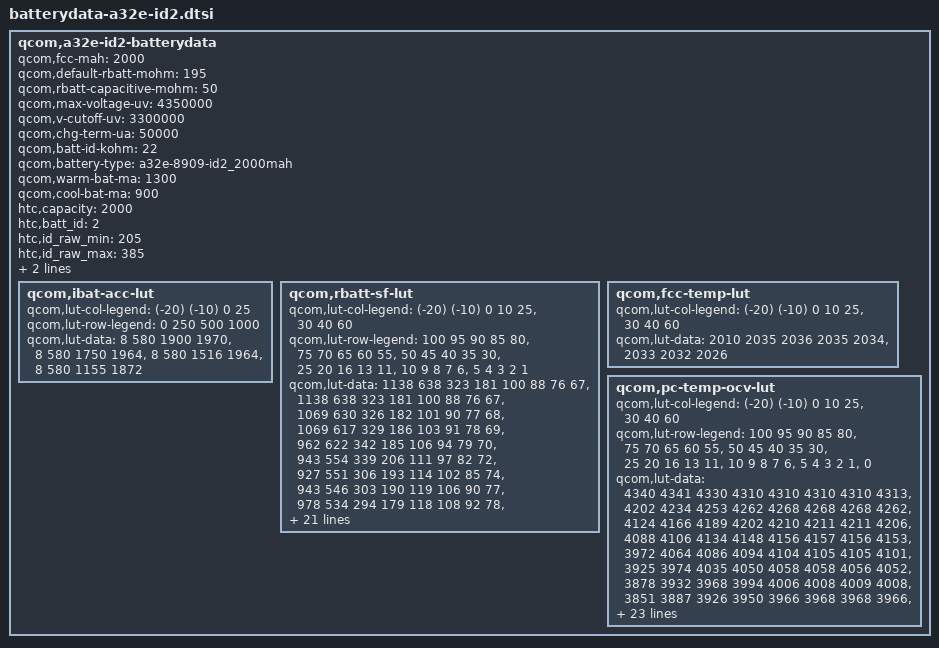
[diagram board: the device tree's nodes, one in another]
/* Copyright (c) 2013, The Linux Foundation. All rights reserved.
 *
 * This program is free software; you can redistribute it and/or modify
 * it under the terms of the GNU General Public License version 2 and
 * only version 2 as published by the Free Software Foundation.
 *
 * This program is distributed in the hope that it will be useful,
 * but WITHOUT ANY WARRANTY; without even the implied warranty of
 * MERCHANTABILITY or FITNESS FOR A PARTICULAR PURPOSE.  See the
 * GNU General Public License for more details.
 */

qcom,a32e-id2-batterydata {
	qcom,fcc-mah = <2000>;
	qcom,default-rbatt-mohm = <195>;
	qcom,rbatt-capacitive-mohm = <50>;
	qcom,max-voltage-uv = <4350000>;
	qcom,v-cutoff-uv = <3300000>;
	qcom,chg-term-ua = <50000>;
	qcom,batt-id-kohm = <22>;
	qcom,battery-type = "a32e-8909-id2_2000mah";
	qcom,warm-bat-ma = <1300>;
	qcom,cool-bat-ma = <900>;
	htc,capacity = <2000>;
	htc,batt_id = <2>;
	htc,id_raw_min = <205>;
	htc,id_raw_max = <385>;
	htc,type = <1>;
	htc,model_name = "B0PKX100";

	qcom,ibat-acc-lut {
		qcom,lut-col-legend = <(-20) (-10) 0 25>;
		qcom,lut-row-legend = <0 250 500 1000>;
		qcom,lut-data = <8 580 1900 1970>,
				<8 580 1750 1964>,
				<8 580 1516 1964>,
				<8 580 1155 1872>;
	};

	qcom,rbatt-sf-lut {
		qcom,lut-col-legend = <(-20) (-10) 0 10 25>,
				<30 40 60>;
		qcom,lut-row-legend = <100 95 90 85 80>,
				<75 70 65 60 55>,
				<50 45 40 35 30>,
				<25 20 16 13 11>,
				<10 9 8 7 6>,
				<5 4 3 2 1>;
		qcom,lut-data = <1138 638 323 181 100 88 76 67>,
				<1138 638 323 181 100 88 76 67>,
				<1069 630 326 182 101 90 77 68>,
				<1069 617 329 186 103 91 78 69>,
				<962 622 342 185 106 94 79 70>,
				<943 554 339 206 111 97 82 72>,
				<927 551 306 193 114 102 85 74>,
				<943 546 303 190 119 106 90 77>,
				<978 534 294 179 118 108 92 78>,
				<1024 550 287 168 102 91 79 70>,
				<1081 582 283 163 98 88 76 68>,
				<1139 636 303 161 99 90 78 70>,
				<1200 684 338 163 101 91 82 73>,
				<1270 738 383 181 101 92 84 75>,
				<1449 797 443 212 104 91 80 73>,
				<1731 867 503 254 111 94 78 69>,
				<2138 934 560 294 122 99 80 70>,
				<2604 1000 613 324 132 107 82 69>,
				<3047 1046 655 347 137 111 83 69>,
				<3273 1035 660 355 136 110 85 71>,
				<3386 1059 681 369 143 115 88 72>,
				<3680 1087 705 385 150 119 90 74>,
				<4026 1117 730 405 159 126 93 76>,
				<4434 1171 757 426 168 132 96 77>,
				<4942 1268 783 444 174 135 96 76>,
				<5607 1411 806 456 176 135 94 74>,
				<6570 1606 834 475 185 141 97 75>,
				<8048 1884 875 506 198 149 102 77>,
				<11056 2318 977 547 215 161 107 81>,
				<22112 3161 1275 604 241 181 120 97>;
	};

	qcom,fcc-temp-lut {
		qcom,lut-col-legend = <(-20) (-10) 0 10 25>,
				<30 40 60>;
		qcom,lut-data = <2010 2035 2036 2035 2034>,
				<2033 2032 2026>;
	};

	qcom,pc-temp-ocv-lut {
		qcom,lut-col-legend = <(-20) (-10) 0 10 25>,
				<30 40 60>;
		qcom,lut-row-legend = <100 95 90 85 80>,
				<75 70 65 60 55>,
				<50 45 40 35 30>,
				<25 20 16 13 11>,
				<10 9 8 7 6>,
				<5 4 3 2 1>,
				<0>;
		qcom,lut-data = <4340 4341 4330 4310 4310 4310 4310 4313>,
				<4202 4234 4253 4262 4268 4268 4268 4262>,
				<4124 4166 4189 4202 4210 4211 4211 4206>,
				<4088 4106 4134 4148 4156 4157 4156 4153>,
				<3972 4064 4086 4094 4104 4105 4105 4101>,
				<3925 3974 4035 4050 4058 4058 4056 4052>,
				<3878 3932 3968 3994 4006 4008 4009 4008>,
				<3851 3887 3926 3950 3966 3968 3968 3966>,
				<3833 3844 3882 3904 3922 3924 3926 3924>,
				<3816 3822 3842 3862 3873 3875 3876 3875>,
				<3800 3808 3810 3828 3840 3842 3844 3844>,
				<3784 3793 3797 3804 3816 3818 3820 3820>,
				<3768 3779 3786 3786 3796 3798 3800 3800>,
				<3752 3764 3776 3778 3780 3782 3784 3782>,
				<3734 3749 3764 3769 3768 3767 3766 3761>,
				<3716 3734 3746 3756 3755 3752 3747 3734>,
				<3694 3719 3724 3733 3733 3730 3724 3712>,
				<3673 3706 3705 3707 3705 3703 3698 3686>,
				<3651 3692 3693 3688 3685 3683 3679 3668>,
				<3633 3681 3684 3682 3680 3678 3675 3665>,
				<3623 3674 3680 3679 3678 3677 3674 3664>,
				<3610 3666 3675 3676 3676 3675 3672 3662>,
				<3594 3656 3670 3672 3673 3672 3669 3659>,
				<3574 3645 3662 3667 3668 3667 3664 3652>,
				<3550 3626 3650 3656 3656 3654 3648 3632>,
				<3516 3600 3624 3630 3626 3623 3615 3594>,
				<3470 3564 3584 3586 3580 3576 3567 3546>,
				<3408 3512 3528 3526 3518 3515 3506 3481>,
				<3320 3437 3448 3446 3436 3432 3422 3394>,
				<3208 3318 3326 3321 3310 3306 3293 3256>,
				<3000 3000 3000 3000 3000 3000 3000 3000>;
	};
};
